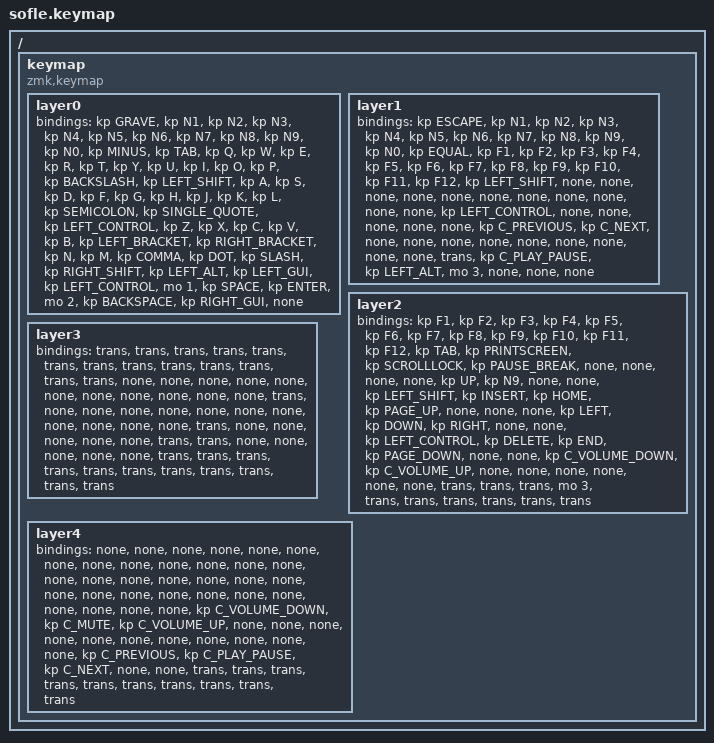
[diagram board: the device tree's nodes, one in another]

  /*
  * Copyright (c) 2020 The ZMK Contributors
  *
  * SPDX-License-Identifier: MIT
  */

  #include <behaviors.dtsi>
  #include <dt-bindings/zmk/keys.h>
  #include <dt-bindings/zmk/bt.h>
  #include <dt-bindings/zmk/ext_power.h>

  / {
    keymap {
      compatible = "zmk,keymap";
  layer0 {
          bindings = <
          &kp GRAVE &kp N1 &kp N2 &kp N3 &kp N4 &kp N5 &kp N6 &kp N7 &kp N8 &kp N9 &kp N0 &kp MINUS &kp TAB &kp Q &kp W &kp E &kp R &kp T &kp Y &kp U &kp I &kp O &kp P &kp BACKSLASH &kp LEFT_SHIFT &kp A &kp S &kp D &kp F &kp G &kp H &kp J &kp K &kp L &kp SEMICOLON &kp SINGLE_QUOTE &kp LEFT_CONTROL &kp Z &kp X &kp C &kp V &kp B &kp LEFT_BRACKET &kp RIGHT_BRACKET &kp N &kp M &kp COMMA &kp DOT &kp SLASH &kp RIGHT_SHIFT &kp LEFT_ALT &kp LEFT_GUI &kp LEFT_CONTROL &mo 1 &kp SPACE &kp ENTER &mo 2 &kp BACKSPACE &kp RIGHT_GUI &none
          >;
        };layer1 {
          bindings = <
          &kp ESCAPE &kp N1 &kp N2 &kp N3 &kp N4 &kp N5 &kp N6 &kp N7 &kp N8 &kp N9 &kp N0 &kp EQUAL &kp F1 &kp F2 &kp F3 &kp F4 &kp F5 &kp F6 &kp F7 &kp F8 &kp F9 &kp F10 &kp F11 &kp F12 &kp LEFT_SHIFT &none &none &none &none &none &none &none &none &none &none &none &kp LEFT_CONTROL &none &none &none &none &none &kp C_PREVIOUS &kp C_NEXT &none &none &none &none &none &none &none &none &none &trans &kp C_PLAY_PAUSE &kp LEFT_ALT &mo 3 &none &none &none
          >;
        };layer2 {
          bindings = <
          &kp F1 &kp F2 &kp F3 &kp F4 &kp F5 &kp F6 &kp F7 &kp F8 &kp F9 &kp F10 &kp F11 &kp F12 &kp TAB &kp PRINTSCREEN &kp SCROLLLOCK &kp PAUSE_BREAK &none &none &none &none &kp UP &kp N9 &none &none &kp LEFT_SHIFT &kp INSERT &kp HOME &kp PAGE_UP &none &none &none &kp LEFT &kp DOWN &kp RIGHT &none &none &kp LEFT_CONTROL &kp DELETE &kp END &kp PAGE_DOWN &none &none &kp C_VOLUME_DOWN &kp C_VOLUME_UP &none &none &none &none &none &none &trans &trans &trans &mo 3 &trans &trans &trans &trans &trans &trans
          >;
        };layer3 {
          bindings = <
          &trans &trans &trans &trans &trans &trans &trans &trans &trans &trans &trans &trans &trans &none &none &none &none &none &none &none &none &none &none &none &trans &none &none &none &none &none &none &none &none &none &none &none &trans &none &none &none &none &none &trans &trans &none &none &none &none &none &trans &trans &trans &trans &trans &trans &trans &trans &trans &trans &trans
          >;
        };layer4 {
          bindings = <
          &none &none &none &none &none &none &none &none &none &none &none &none &none &none &none &none &none &none &none &none &none &none &none &none &none &none &none &none &none &none &none &kp C_VOLUME_DOWN &kp C_MUTE &kp C_VOLUME_UP &none &none &none &none &none &none &none &none &none &none &none &kp C_PREVIOUS &kp C_PLAY_PAUSE &kp C_NEXT &none &none &trans &trans &trans &trans &trans &trans &trans &trans &trans &trans
          >;
        };
    };
  };
  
